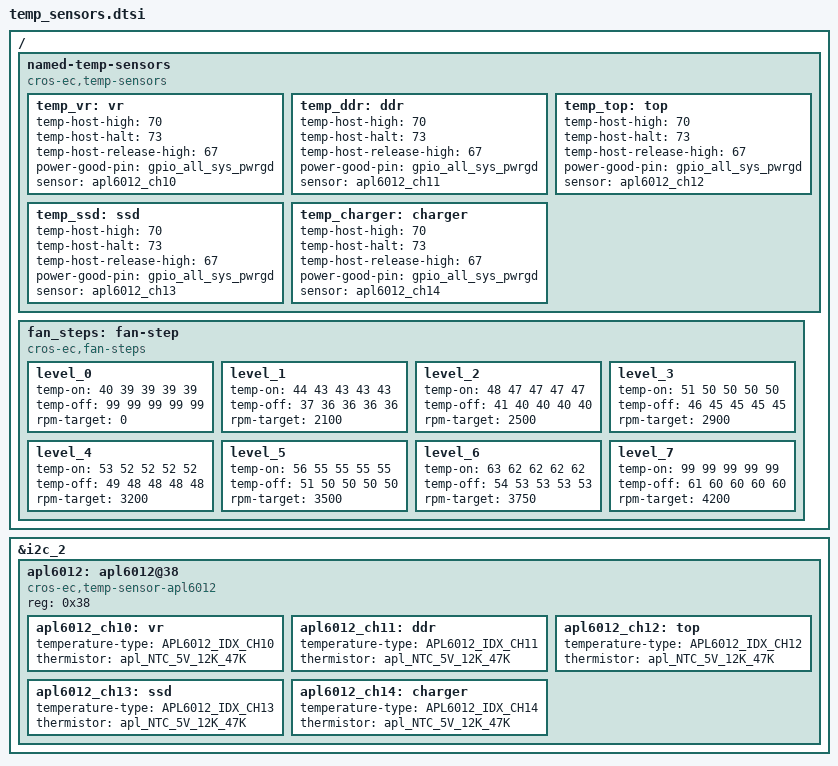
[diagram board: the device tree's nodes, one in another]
/* Copyright 2025 The ChromiumOS Authors
 * Use of this source code is governed by a BSD-style license that can be
 * found in the LICENSE file.
 */
#include <cros/thermistor/thermistor.dtsi>

/ {
	named-temp-sensors {
		compatible = "cros-ec,temp-sensors";

		temp_vr: vr {
			temp-host-high = <70>;
			temp-host-halt = <73>;
			temp-host-release-high = <67>;
			power-good-pin = <&gpio_all_sys_pwrgd>;
			sensor = <&apl6012_ch10>;
		};
		temp_ddr: ddr {
			temp-host-high = <70>;
			temp-host-halt = <73>;
			temp-host-release-high = <67>;
			power-good-pin = <&gpio_all_sys_pwrgd>;
			sensor = <&apl6012_ch11>;
		};
		temp_top: top {
			temp-host-high = <70>;
			temp-host-halt = <73>;
			temp-host-release-high = <67>;
			power-good-pin = <&gpio_all_sys_pwrgd>;
			sensor = <&apl6012_ch12>;
		};
		temp_ssd: ssd {
			temp-host-high = <70>;
			temp-host-halt = <73>;
			temp-host-release-high = <67>;
			power-good-pin = <&gpio_all_sys_pwrgd>;
			sensor = <&apl6012_ch13>;
		};
		temp_charger: charger {
			temp-host-high = <70>;
			temp-host-halt = <73>;
			temp-host-release-high = <67>;
			power-good-pin = <&gpio_all_sys_pwrgd>;
			sensor = <&apl6012_ch14>;
		};
	};

	fan_steps: fan-step {
		compatible = "cros-ec,fan-steps";
		level_0 {
			temp-on = <40 39 39 39 39>;
			temp-off = <99 99 99 99 99>;
			rpm-target = <0>;
		};
		level_1 {
			temp-on = <44 43 43 43 43>;
			temp-off = <37 36 36 36 36>;
			rpm-target = <2100>;
		};
		level_2 {
			temp-on = <48 47 47 47 47>;
			temp-off = <41 40 40 40 40>;
			rpm-target = <2500>;
		};
		level_3 {
			temp-on = <51 50 50 50 50>;
			temp-off = <46 45 45 45 45>;
			rpm-target = <2900>;
		};
		level_4 {
			temp-on = <53 52 52 52 52>;
			temp-off = <49 48 48 48 48>;
			rpm-target = <3200>;
		};
		level_5 {
			temp-on = <56 55 55 55 55>;
			temp-off = <51 50 50 50 50>;
			rpm-target = <3500>;
		};
		level_6 {
			temp-on = <63 62 62 62 62>;
			temp-off = <54 53 53 53 53>;
			rpm-target = <3750>;
		};
		level_7 {
			temp-on = <99 99 99 99 99>;
			temp-off = <61 60 60 60 60>;
			rpm-target = <4200>;
		};
	};
};

&i2c_2 {
	apl6012: apl6012@38 {
		compatible = "cros-ec,temp-sensor-apl6012";
		reg = <0x38>;

		apl6012_ch10: vr {
			temperature-type = "APL6012_IDX_CH10";
			thermistor = <&apl_NTC_5V_12K_47K>;
		};
		apl6012_ch11: ddr {
			temperature-type = "APL6012_IDX_CH11";
			thermistor = <&apl_NTC_5V_12K_47K>;
		};
		apl6012_ch12: top {
			temperature-type = "APL6012_IDX_CH12";
			thermistor = <&apl_NTC_5V_12K_47K>;
		};
		apl6012_ch13: ssd {
			temperature-type = "APL6012_IDX_CH13";
			thermistor = <&apl_NTC_5V_12K_47K>;
		};
		apl6012_ch14: charger {
			temperature-type = "APL6012_IDX_CH14";
			thermistor = <&apl_NTC_5V_12K_47K>;
		};
	};
};
